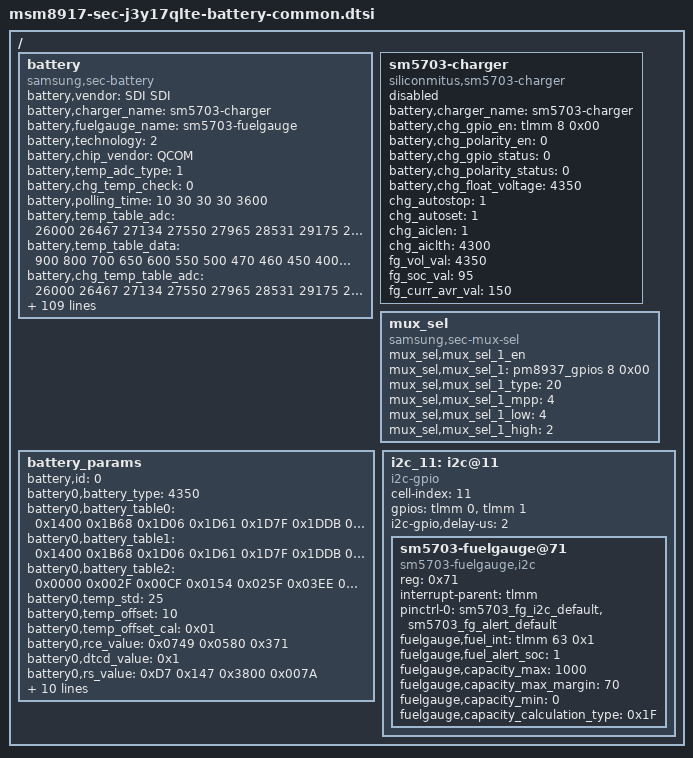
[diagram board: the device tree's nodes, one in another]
/* Copyright (c) 2015, The Linux Foundation. All rights reserved.
 *
 * This program is free software; you can redistribute it and/or modify
 * it under the terms of the GNU General Public License version 2 and
 * only version 2 as published by the Free Software Foundation.
 *
 * This program is distributed in the hope that it will be useful,
 * but WITHOUT ANY WARRANTY; without even the implied warranty of
 * MERCHANTABILITY or FITNESS FOR A PARTICULAR PURPOSE.  See the
 * GNU General Public License for more details.
 */

/ {
	battery {
		status = "okay";
		compatible = "samsung,sec-battery";
		battery,vendor = "SDI SDI";
		battery,charger_name = "sm5703-charger";
		battery,fuelgauge_name = "sm5703-fuelgauge";
		battery,technology = <2>; /* POWER_SUPPLY_TECHNOLOGY_LION */

		battery,chip_vendor = "QCOM";
		battery,temp_adc_type = <1>; /* SEC_BATTERY_ADC_TYPE_AP */

		battery,chg_temp_check = <0>;

		battery,polling_time = <10 30 30 30 3600>;

		battery,temp_table_adc = <26000 26467 27134 27550 27965 28531 29175 29600 29760 29919 30792 32737 34869 37004 38534 38861 39764 40457 41041 41518>;

		battery,temp_table_data = <900 800 700 650 600 550 500 470 460 450 400 300 200 100 20 0 (-50) (-100) (-150) (-200)>;

		battery,chg_temp_table_adc = <26000 26467 27134 27550 27965 28531 29175 29600 29760 29919 30792 32737 34869 37004 38534 38861 39764 40457 41041 41518>;

		battery,chg_temp_table_data = <900 800 700 650 600 550 500 470 460 450 400 300 200 100 20 0 (-50) (-100) (-150) (-200)>;

		battery,siop_input_limit_current = <1000>;
		battery,siop_charging_limit_current = <2100>;
		battery,siop_hv_input_limit_current = <700>;
		battery,siop_hv_charging_limit_current = <1000>;

		battery,siop_wireless_input_limit_current = <700>;
		battery,siop_wireless_charging_limit_current = <600>;
		battery,siop_hv_wireless_input_limit_current = <500>;
		battery,siop_hv_wireless_charging_limit_current = <1000>;
		battery,siop_call_cv_current = <500>;
		battery,siop_call_cc_current = <500>;

		battery,input_current_limit = <1550 500 500 1550 500 900 1000 500 500 1000 820 1550 1550 500 1000 300 700 1000 1000 300 80 500 1000 1000 1000 1000 900 820 820 500 1000 1000 820 820 820 820 820 820>;
		battery,fast_charging_current = <1600 0 500 1600 500 1200 1000 500 0 1200 1000 1600 1600 0 1300 300 700 1300 1500 300 80 0 1600 1000 1600 1400 1200 1000 1000 0 0 1000 1000 1000 1000 1000 1000 1000>;
		battery,full_check_current_1st = <200 0 200 200 200 200 200 200 0 200 200 200 200 0 200 200 200 200 200 200 200 0 200 200 200 200 200 200 200 0 0 200 200 200 200 200 200 200>;
		battery,full_check_current_2nd = <100 0 100 100 100 100 100 100 0 100 100 100 100 0 100 100 100 100 100 100 100 0 100 100 100 100 100 100 100 0 0 100 100 100 100 100 100 100>;

		battery,step_charging_type = <0x1>; /* STEP_CHARGING_CONDITION_VOLTAGE */
		battery,step_charging_condtion = <4100 4400>;
		battery,step_charging_current = <3960 3300>; /* 1.2C  1C */

		battery,adc_check_count = <5>;

		battery,cable_check_type = <4>; /* SEC_BATTERY_CABLE_CHECK_PSY */
		battery,cable_source_type = <3>; /* SEC_BATTERY_CABLE_SOURCE_EXTERNAL */
		battery,event_waiting_time = <600>;
		battery,polling_type = <1>; /* SEC_BATTERY_MONITOR_ALARM */
		battery,monitor_initial_count = <3>;

		battery,battery_check_type = <4>; /* SEC_BATTERY_CHECK_FUELGAUGE */
		battery,check_count = <0>;
		battery,check_adc_max = <1440>;
		battery,check_adc_min = <0>;

		battery,ovp_uvlo_check_type = <3>; /* SEC_BATTERY_OVP_UVLO_CHGPOLLING */

		battery,thermal_source = <2>; /* SEC_BATTERY_THERMAL_SOURCE_ADC */
		battery,chg_thermal_source = <0>;
		battery,mux_channel = <4>;

		battery,temp_check_type = <2>; /* SEC_BATTERY_TEMP_CHECK_TEMP */
		battery,temp_check_count = <1>;
		battery,temp_highlimit_threshold_event = <800>;
		battery,temp_highlimit_recovery_event = <750>;
		battery,temp_high_threshold_event = <500>;
		battery,temp_high_recovery_event = <450>;
		battery,temp_low_threshold_event = <0>;
		battery,temp_low_recovery_event = <50>;
		battery,temp_highlimit_threshold_normal = <800>;
		battery,temp_highlimit_recovery_normal = <750>;
		battery,temp_high_threshold_normal = <500>;
		battery,temp_high_recovery_normal = <450>;
		battery,temp_low_threshold_normal = <0>;
		battery,temp_low_recovery_normal = <50>;
		battery,temp_highlimit_threshold_lpm = <800>;
		battery,temp_highlimit_recovery_lpm = <750>;
		battery,temp_high_threshold_lpm = <500>;
		battery,temp_high_recovery_lpm = <450>;
		battery,temp_low_threshold_lpm = <0>;
		battery,temp_low_recovery_lpm = <50>;
		battery,full_check_type = <2>; /* SEC_BATTERY_FULLCHARGED_FG_CURRENT */
		battery,full_check_type_2nd = <2>; /* SEC_BATTERY_FULLCHARGED_FG_CURRENT */
		battery,full_check_count = <1>;
		battery,chg_gpio_full_check = <0>;
		battery,chg_polarity_full_check = <1>;

		battery,chg_high_temp_1st = <465>;
		battery,chg_high_temp_2nd = <465>;
		battery,chg_high_temp_recovery = <455>;
		battery,chg_charging_limit_current = <1400>;
		battery,chg_charging_limit_current_2nd = <1400>;
		battery,chg_skip_check_capacity = <10>;
		battery,chg_skip_check_time = <600>;

		/* SEC_BATTERY_FULL_CONDITION_SOC |
		   SEC_BATTERY_FULL_CONDITION_NOTIMEFULL |
		   SEC_BATTERY_FULL_CONDITION_VCELL */
		battery,full_condition_type = <13>;
		battery,full_condition_soc = <93>;
		battery,full_condition_vcell = <4240>;

		battery,recharge_check_count = <1>;
		battery,recharge_condition_type = <4>; /* SEC_BATTERY_RECHARGE_CONDITION_VCELL */
		battery,recharge_condition_soc = <98>;
		battery,recharge_condition_vcell = <4300>;

		//battery,self_discharging_en;
		battery,self_discharging_type = <2>;	/* SEC_BAT_SELF_DISCHARGING_BY_CHG */
		//battery,factory_discharging = <&expander_gpios 13 0x00>;

		battery,force_discharging_limit = <600>;
		battery,force_discharging_recov = <550>;
		battery,self_discharging_voltage_limit = <4250>;
		battery,discharging_adc_max = <29864>;
		battery,discharging_adc_min = <25768>;
		battery,discharging_ntc_limit = <2750>;

		battery,charging_total_time = <21600>;
		battery,recharging_total_time = <5400>;
		battery,charging_reset_time = <0>;

		battery,swelling_high_temp_block = <410>;
		battery,swelling_high_temp_recov = <360>;
		battery,swelling_low_temp_block_1st = <150>;
		battery,swelling_low_temp_recov_1st = <200>;
		battery,swelling_low_temp_block_2nd = <50>;
		battery,swelling_low_temp_recov_2nd = <100>;
		//battery,swelling_chg_current = <1500>;
		battery,swelling_high_temp_current = <1100>;
		battery,swelling_low_temp_current = <1100>;
		battery,swelling_low_temp_topoff = <100>;
		battery,swelling_high_temp_topoff = <100>;
		battery,swelling_drop_float_voltage = <4150>;
		battery,swelling_high_rechg_voltage = <4100>;
		battery,swelling_low_rechg_voltage = <4000>;
		battery,swelling_block_time = <600>;

		battery,self_discharging_temp_block = <600>;
		battery,self_discharging_volt_block = <4250>;
		battery,self_discharging_temp_recov = <550>;
		battery,self_discharging_temp_pollingtime = <400>;

		battery,chg_float_voltage = <4350>;

		qcom,sec-battery-vadc = <&pm8937_vadc>;
	};

	sm5703-charger {
		status = "disable";
		compatible = "siliconmitus,sm5703-charger";

		/* Charger */
		battery,charger_name = "sm5703-charger";
		battery,chg_gpio_en = <&tlmm 8 0x00>;
		battery,chg_polarity_en = <0>;
		battery,chg_gpio_status = <0>;
		battery,chg_polarity_status = <0>;
		battery,chg_float_voltage = <4350>;
		chg_autostop = <1>;
		chg_autoset = <1>;
		chg_aiclen = <1>;
		chg_aiclth = <4300>;
		fg_vol_val = <4350>;
		fg_soc_val = <95>;
		fg_curr_avr_val = <150>;
	};

/* need to confirm*/
	mux_sel {
		compatible = "samsung,sec-mux-sel";
		mux_sel,mux_sel_1_en;
		mux_sel,mux_sel_1 = <&pm8937_gpios 8 0x00>;
		mux_sel,mux_sel_1_type = <20>; /* BATT_THM_MUX_SEL | AP_THM_MUX_SEL */
		mux_sel,mux_sel_1_mpp = <4>; /* SEC_MPP4_MUX_SEL */
		mux_sel,mux_sel_1_low = <4>; /* SEC_MUX_SEL_AP_THM */
		mux_sel,mux_sel_1_high = <2>; /* SEC_MUX_SEL_BATT_THM */
	};
	
	battery_params {
		battery,id = <0>; /* -1 means auto, detected by F/G */
		battery0,battery_type = <4350>; /* 4200 4350 4400 */
		battery0,battery_table0 = <0x1400 0x1B68 0x1D06 0x1D61 0x1D7F 0x1DDB 0x1E28 0x1E80 0x1EE9 0x1F70 0x1FF1 0x2037 0x209D 0x2189 0x225C 0x2400>;
		battery0,battery_table1 = <0x1400 0x1B68 0x1D06 0x1D61 0x1D7F 0x1DDB 0x1E28 0x1E80 0x1EE9 0x1F70 0x1FF1 0x2037 0x209D 0x2189 0x225C 0x2400>;
		battery0,battery_table2 = <0x0000 0x002F 0x00CF 0x0154 0x025F 0x03EE 0x0687 0x0921 0x0B36 0x0CC5 0x0E54 0x0ED9 0x0FE4 0x1213 0x13BD 0x13CC>;
		battery0,temp_std = <25>;
		battery0,temp_offset = <10>;
		battery0,temp_offset_cal = <0x01>;
		battery0,rce_value = <0x0749 0x0580 0x371>;
        battery0,dtcd_value = <0x1>;
        battery0,rs_value = <0xD7 0x147 0x3800 0x007A>; /*rs mix_factor max min*/
        battery0,vit_period = <0x3506>;
        battery0,mix_value = <0x0403 0x0004>; /*mix_rate init_blank*/
        battery0,topoff_soc = <0x0 0x5>; /*enable soc*/
		battery0,tem_poff = <3400 100 3320 100>;
		battery0,charge_offset_cal = <0x02>;
        battery0,volt_cal = <0x809E>;
        battery0,curr_cal = <0x7B85>;
		battery0,ext_temp_cal = <0 10 1 1 1 7 1 1>;
		battery0,v_alarm = <3100>;
		battery0,data_ver = <0x02>;
	};

	i2c_11: i2c@11 {
		cell-index = <11>;
		compatible = "i2c-gpio";
		gpios = <&tlmm 0 0	/* sda */
			&tlmm 1 0	/* scl */
			>;
		i2c-gpio,delay-us = <2>;
		#address-cells = <1>;
		#size-cells = <0>;

		sm5703-fuelgauge@71{
			status = "okay";
			compatible = "sm5703-fuelgauge,i2c";
			reg = <0x71>;
			interrupt-parent = <&tlmm>;
			pinctrl-names = "default";
			pinctrl-0 = <&sm5703_fg_i2c_default &sm5703_fg_alert_default>;
			//fuelgauge,bat_int = <&tlmm 45 0x1>;
			fuelgauge,fuel_int = <&tlmm 63 0x1>;
			fuelgauge,fuel_alert_soc = <1>;
			fuelgauge,capacity_max = <1000>;
			fuelgauge,capacity_max_margin = <70>;
			fuelgauge,capacity_min = <0>;
			fuelgauge,capacity_calculation_type = <0x1F>;
		};
	};
};
